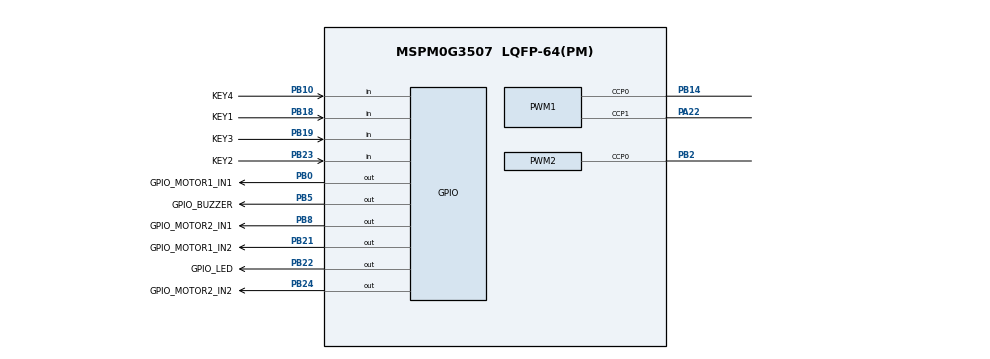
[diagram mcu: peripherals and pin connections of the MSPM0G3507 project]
/**
 * These arguments were used when this file was generated. They will be automatically applied on subsequent loads
 * via the GUI or CLI. Run CLI with '--help' for additional information on how to override these arguments.
 * @cliArgs --device "MSPM0G350X" --part "Default" --package "LQFP-64(PM)" --product "mspm0_sdk@2.10.00.04"
 * @v2CliArgs --device "MSPM0G3507" --package "LQFP-64(PM)" --product "mspm0_sdk@2.10.00.04"
 * @versions {"tool":"1.26.2+4477"}
 */

/**
 * Import the modules used in this configuration.
 */
const GPIO   = scripting.addModule("/ti/driverlib/GPIO", {}, false);
const GPIO1  = GPIO.addInstance();
const GPIO2  = GPIO.addInstance();
const GPIO3  = GPIO.addInstance();
const GPIO4  = GPIO.addInstance();
const PWM    = scripting.addModule("/ti/driverlib/PWM", {}, false);
const PWM1   = PWM.addInstance();
const PWM2   = PWM.addInstance();
const SYSCTL = scripting.addModule("/ti/driverlib/SYSCTL");
const TIMER  = scripting.addModule("/ti/driverlib/TIMER", {}, false);
const TIMER1 = TIMER.addInstance();
const TIMER2 = TIMER.addInstance();

/**
 * Write custom configuration values to the imported modules.
 */
const divider6       = system.clockTree["PLL_CLK2X_DIV"];
divider6.divideValue = 4;

const divider7       = system.clockTree["PLL_PDIV"];
divider7.divideValue = 2;

const divider9       = system.clockTree["UDIV"];
divider9.divideValue = 2;

const multiplier2         = system.clockTree["PLL_QDIV"];
multiplier2.multiplyValue = 10;

const mux8       = system.clockTree["HSCLKMUX"];
mux8.inputSelect = "HSCLKMUX_SYSPLL2X";

GPIO1.$name                             = "GPIO_BUZZERs";
GPIO1.associatedPins[0].ioStructure     = "SD";
GPIO1.associatedPins[0].subChanID       = 1;
GPIO1.associatedPins[0].subOutputPolicy = "TOGGLE";
GPIO1.associatedPins[0].initialValue    = "SET";
GPIO1.associatedPins[0].$name           = "GPIO_BUZZER";
GPIO1.associatedPins[0].pin.$assign     = "PB5";

const Board = scripting.addModule("/ti/driverlib/Board", {}, false);

GPIO2.$name                         = "GPIO_MOTORs";
GPIO2.associatedPins.create(4);
GPIO2.associatedPins[0].ioStructure = "SD";
GPIO2.associatedPins[0].$name       = "GPIO_MOTOR1_IN1";
GPIO2.associatedPins[0].pin.$assign = "PB0";
GPIO2.associatedPins[1].ioStructure = "SD";
GPIO2.associatedPins[1].$name       = "GPIO_MOTOR1_IN2";
GPIO2.associatedPins[1].pin.$assign = "PB21";
GPIO2.associatedPins[2].ioStructure = "SD";
GPIO2.associatedPins[2].$name       = "GPIO_MOTOR2_IN1";
GPIO2.associatedPins[2].pin.$assign = "PB8";
GPIO2.associatedPins[3].ioStructure = "SD";
GPIO2.associatedPins[3].$name       = "GPIO_MOTOR2_IN2";
GPIO2.associatedPins[3].pin.$assign = "PB24";

GPIO3.$name                              = "GPIO_KEYs";
GPIO3.associatedPins.create(4);
GPIO3.associatedPins[0].$name            = "KEY1";
GPIO3.associatedPins[0].direction        = "INPUT";
GPIO3.associatedPins[0].ioStructure      = "SD";
GPIO3.associatedPins[0].internalResistor = "PULL_DOWN";
GPIO3.associatedPins[0].pin.$assign      = "PB18";
GPIO3.associatedPins[1].$name            = "KEY2";
GPIO3.associatedPins[1].direction        = "INPUT";
GPIO3.associatedPins[1].ioStructure      = "SD";
GPIO3.associatedPins[1].internalResistor = "PULL_DOWN";
GPIO3.associatedPins[1].pin.$assign      = "PB23";
GPIO3.associatedPins[2].$name            = "KEY3";
GPIO3.associatedPins[2].direction        = "INPUT";
GPIO3.associatedPins[2].ioStructure      = "SD";
GPIO3.associatedPins[2].internalResistor = "PULL_DOWN";
GPIO3.associatedPins[2].pin.$assign      = "PB19";
GPIO3.associatedPins[3].$name            = "KEY4";
GPIO3.associatedPins[3].direction        = "INPUT";
GPIO3.associatedPins[3].ioStructure      = "SD";
GPIO3.associatedPins[3].internalResistor = "PULL_DOWN";
GPIO3.associatedPins[3].pin.$assign      = "PB10";

GPIO4.$name                         = "GPIO_LEDs";
GPIO4.associatedPins[0].$name       = "GPIO_LED";
GPIO4.associatedPins[0].ioStructure = "SD";
GPIO4.associatedPins[0].pin.$assign = "PB22";

PWM1.pwmMode                            = "EDGE_ALIGN_UP";
PWM1.timerCount                         = 10000;
PWM1.$name                              = "PWM_MOTOR";
PWM1.peripheral.$assign                 = "TIMA0";
PWM1.peripheral.ccp0Pin.$assign         = "PB14";
PWM1.peripheral.ccp1Pin.$assign         = "PA22";
PWM1.PWM_CHANNEL_0.$name                = "ti_driverlib_pwm_PWMTimerCC0";
PWM1.PWM_CHANNEL_1.$name                = "ti_driverlib_pwm_PWMTimerCC1";
PWM1.ccp0PinConfig.$name                = "ti_driverlib_gpio_GPIOPinGeneric0";
PWM1.ccp0PinConfig.direction            = scripting.forceWrite("OUTPUT");
PWM1.ccp0PinConfig.hideOutputInversion  = scripting.forceWrite(false);
PWM1.ccp0PinConfig.onlyInternalResistor = scripting.forceWrite(false);
PWM1.ccp0PinConfig.passedPeripheralType = scripting.forceWrite("Digital");
PWM1.ccp1PinConfig.$name                = "ti_driverlib_gpio_GPIOPinGeneric1";
PWM1.ccp1PinConfig.direction            = scripting.forceWrite("OUTPUT");
PWM1.ccp1PinConfig.hideOutputInversion  = scripting.forceWrite(false);
PWM1.ccp1PinConfig.onlyInternalResistor = scripting.forceWrite(false);
PWM1.ccp1PinConfig.passedPeripheralType = scripting.forceWrite("Digital");

PWM2.$name                              = "PWM_SERVO";
PWM2.clockDivider                       = 8;
PWM2.pwmMode                            = "EDGE_ALIGN_UP";
PWM2.ccIndex                            = [0];
PWM2.clockPrescale                      = 2;
PWM2.timerCount                         = 20000;
PWM2.PWM_CHANNEL_0.$name                = "ti_driverlib_pwm_PWMTimerCC2";
PWM2.PWM_CHANNEL_0.initVal              = "HIGH";
PWM2.PWM_CHANNEL_0.dutyCycle            = 7.5;
PWM2.ccp0PinConfig.$name                = "ti_driverlib_gpio_GPIOPinGeneric2";
PWM2.ccp0PinConfig.direction            = scripting.forceWrite("OUTPUT");
PWM2.ccp0PinConfig.hideOutputInversion  = scripting.forceWrite(false);
PWM2.ccp0PinConfig.onlyInternalResistor = scripting.forceWrite(false);
PWM2.ccp0PinConfig.passedPeripheralType = scripting.forceWrite("Digital");
PWM2.peripheral.$assign                 = "TIMA1";
PWM2.peripheral.ccp0Pin.$assign         = "PB2";

SYSCTL.forceDefaultClkConfig = true;
SYSCTL.clockTreeEn           = true;

TIMER1.$name              = "PIT_FOR_CUSTOM";
TIMER1.timerClkDiv        = 8;
TIMER1.timerMode          = "PERIODIC_UP";
TIMER1.interrupts         = ["LOAD"];
TIMER1.timerStartTimer    = true;
TIMER1.timerPeriod        = "1ms";
TIMER1.peripheral.$assign = "TIMG12";

TIMER2.$name              = "PIT_FOR_CONTROL";
TIMER2.timerMode          = "PERIODIC_UP";
TIMER2.timerPeriod        = "20 ms";
TIMER2.timerClkPrescale   = 40;
TIMER2.interrupts         = ["LOAD"];
TIMER2.timerStartTimer    = true;
TIMER2.peripheral.$assign = "TIMG0";

/**
 * Pinmux solution for unlocked pins/peripherals. This ensures that minor changes to the automatic solver in a future
 * version of the tool will not impact the pinmux you originally saw.  These lines can be completely deleted in order to
 * re-solve from scratch.
 */
Board.peripheral.$suggestSolution          = "DEBUGSS";
Board.peripheral.swclkPin.$suggestSolution = "PA20";
Board.peripheral.swdioPin.$suggestSolution = "PA19";
